# RN831X_RN861X_MCU register map
File version: v0.0.1
CPU: RN831X_RN861X_MCU r1p0, little endian, MPU, no FPU
Registers are 32-bit, read-write, reset 0x0 unless marked. A register's access mark holds for its fields unless they carry their own. Offsets are from the block's base; [hi:lo] are bit positions.

## QSPI0 — QSPI0 Module
Base 0xB0088000
Same registers: QSPI1 0xB008C000
0x00 SCKDIV access not given — Clock Divisor Register
  [11:0] SCKDIV — Clock divisor factor selection bits
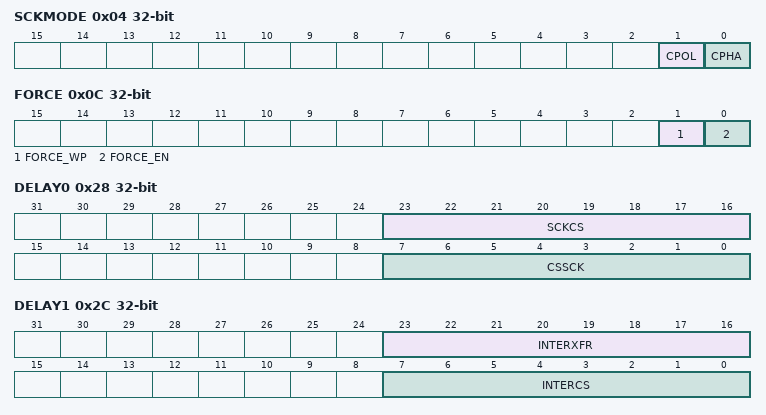
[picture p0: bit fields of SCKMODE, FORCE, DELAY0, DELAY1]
0x04 SCKMODE — Clock Mode Register (Master/Slave)
  [1] CPOL — Clock (SCK) Polarity selection bit.
  [0] CPHA — Clock (SCK) Phase selection bit. In DDR mode, only CPHA=0 is supported
0x08 SCKSAMPLE access not given — Sample Point Configuration Register (DDR Mode)
  [11:0] SCKSMP — DDR Mode SCK sample point delay selection bit
0x0C FORCE — Pin Output Force Register
  [1] FORCE_WP — WP (IO2) pin output state selection bit (when not used as data line). Invalid in Quad-line mode.
  [0] FORCE_EN — Force output enable for non-data pins in different interface modes.
0x10 CSID access not given — Chip Select ID Register
  [2:0] CSID — Chip Select device ID selection bit
0x14 CSDEF access not given — Chip Select Default Value Register
  [0] CSDEF — CS0 default (idle) state selection bit (Master mode)
0x18 CSMODE — Chip Select Mode Register
  [1:0] CSMODE — Chip Select mode selection bits. Use Hold mode for continuous data transfer, switch to Disable mode after transfer completes.
    0=AUTO (Auto mode); 2=HOLD (Hold mode); 3=DISABLE (Disable mode)
0x1C VERSION ro
  [31:0] VERSION — QSPI Version 2.1.0
0x20 ADDR_WRAP access not given — SPI Flash Start Address Offset Register
  [31:0] OFFSET — SPI Flash start address offset value
0x24 BOUNDARY_CFG access not given — SPI Flash Address Boundary Configuration Register
  [31:0] BOUNDARY — XIP boundary address configuration register
0x28 DELAY0 — Delay Control Register 0
  [23:16] SCKCS — Delay cycles from last valid SCK edge to CS deassertion (rising edge).
  [7:0] CSSCK — Delay cycles from CS assertion (falling edge) to first valid SCK rising edge.
0x2C DELAY1 — Delay Control Register 1
  [23:16] INTERXFR — Delay cycles between two data frames.
  [7:0] INTERCS — Minimum delay cycles from CS deassertion (rising edge) to next CS assertion (falling edge).
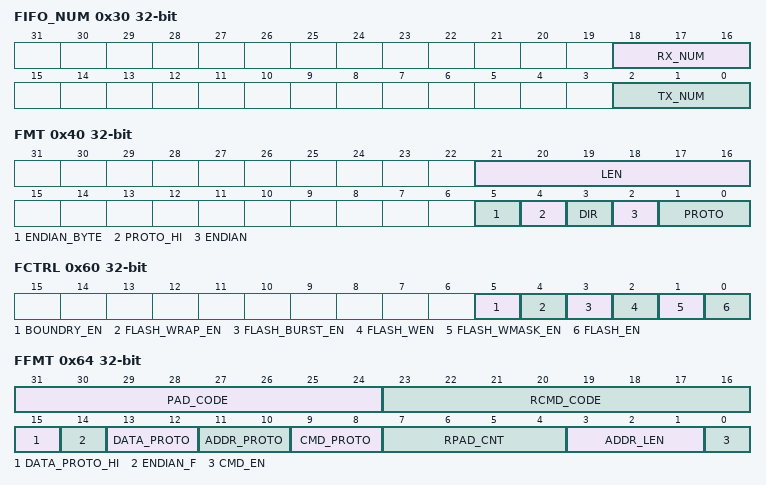
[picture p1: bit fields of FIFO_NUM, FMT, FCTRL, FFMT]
0x30 FIFO_NUM ro — FIFO Valid Data Count Register
  [18:16] RX_NUM — RX FIFO valid data count.
  [2:0] TX_NUM — TX FIFO valid data count.
0x34 TSIZE access not given — DMA Transfer Data Length Register.
  [31:0] TSIZE — transfer data length (in beats)
0x38 RSIZE access not given — DMA Receive Data Length Register.
  [31:0] RSIZE — receive data length (in beats).
0x40 FMT — Frame Format Register (Master/Slave, Non-XIP Mode)
  [21:16] LEN — Frame data bit width selection bits. Master mode supports 4-32 bits, Slave mode supports 8/16/32 bits.
    8=8BIT (Data length for SPI transfer: 8 bits); 16=16BIT (Data length for SPI transfer: 16 bits); 32=32BIT (Data length for SPI transfer: 32 bits)
  [5] ENDIAN_BYTE — Byte endianness (transmission order within 32-bit word).
  [4] PROTO_HI — High bit extension for QSPI_FMT.PROTO[1:0] (See PROTO below).
  [3] DIR — Pin data transfer direction selection bit (for configurable I/O pins).
  [2] ENDIAN — Bit endianness (transmission order within byte).
  [1:0] PROTO — Interface mode (number of data lines) selection bits.
    0=SINGLE (Single-line mode); 1=DUAL (Dual-line mode); 2=QUAD (Quad-line mode); 3=HALF_DUPLEX (Single-line Half-duplex mode)
0x48 TXDATA access not given — Transmit Data Register (Master/Slave)
  [31:0] TXDATA — Transmit data buffer. Valid data width depends on QSPI_FMT.LEN register configuration.
0x4C RXDATA ro — Receive Data Register (Master/Slave)
  [31:0] RXDATA — Receive data buffer. Valid data width depends on QSPI_FMT.LEN register configuration.
0x50 TX_MARK — Transmit FIFO Threshold Register (Master/Slave)
  [2:0] TX_MARK — ransmit FIFO threshold selection bit. Interrupt flag tx_irq is raised when TX FIFO valid data count is less than this threshold.
    1=1 valid data item; 2=2 valid data items; 3=3 valid data items; 4=4 valid data items
0x54 RX_MARK — Receive FIFO Threshold Register (Master/Slave)
  [2:0] RX_MARK — Receive FIFO threshold selection bit. Interrupt flag rx_irq is raised when RX FIFO valid data count exceeds this threshold.
    0=0 valid data item; 1=1 valid data item; 2=2 valid data items; 3=3 valid data items
0x60 FCTRL — SPI Flash Interface Control Register (XIP)
  [5] BOUNDRY_EN — XIP Mode Boundary Address Enable bit
  [4] FLASH_WRAP_EN — Data value for fixed data measurement mode. The measurement register is updated only when this data is received
  [3] FLASH_BURST_EN — Measurement End Point
  [2] FLASH_WEN — Measurement Start Point
  [1] FLASH_WMASK_EN — Measurement Mode
  [0] FLASH_EN — XIP Mode Enable bit.
0x64 FFMT — SPI Flash Command Format Register (XIP)
  [31:24] PAD_CODE — First 8 bits of data transmitted during dummy cycles.
  [23:16] RCMD_CODE — SPI Flash Read Instruction Opcode.
  [15] DATA_PROTO_HI — High bit extension for QSPI_FFMT.DATA_PROTO[1:0] (See DATA_PROTO).
  [14] ENDIAN_F — XIP Mode bit endianness (transmission order within byte). This bit does not change byte order, only the bit order within a single byte.
  [13:12] DATA_PROTO — Data Phase Interface Mode selection bits.
    0=SINGLE (XIP Data Single-line mode); 1=DUAL (XIP Data Dual-line mode); 2=QUAD (XIP Data Quad-line mode); 3=HALF_DUPLEX (XIP Data Single-line Half-duplex mode)
  [11:10] ADDR_PROTO — Address Phase Interface Mode selection bits.
    0=SINGLE (XIP Address Single-line mode); 1=DUAL (XIP Address Dual-line mode); 2=QUAD (XIP Address Quad-line mode)
  [9:8] CMD_PROTO — Command Phase Interface Mode selection bits.
    0=SINGLE (XIP Command Single-line mode); 1=DUAL (XIP Command Dual-line mode); 2=QUAD (XIP Command Quad-line mode)
  [7:4] RPAD_CNT — Read instruction dummy cycle count selection bits (Lower 4 bits). The 5th bit (MSB) of RPAD_CNT is configured in FFMT1.RPAD_CNT_H.
  [3:1] ADDR_LEN — Address Length selection bits.
    0=NONE (Skip Address phase); 1=8BIT (Address Length 8 bits); 2=16BIT (Address Length 16 bits); 3=24BIT (Address Length 24 bits (default)); 4=32BIT (Address Length 32 bits)
  [0] CMD_EN — Instruction Send Enable bit.
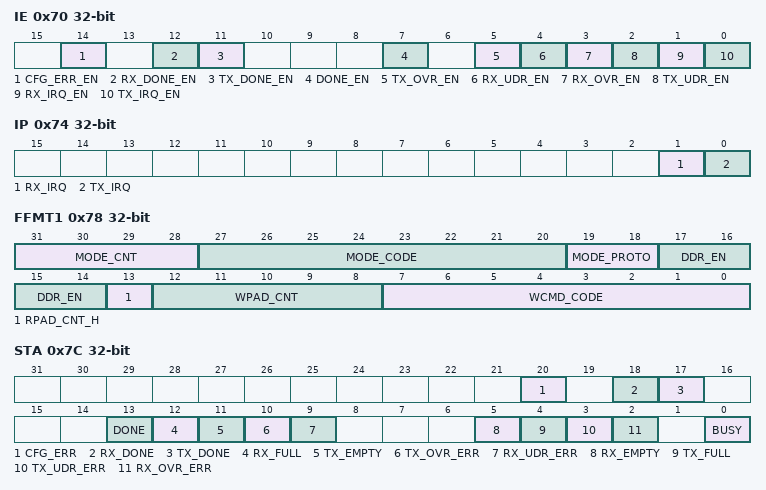
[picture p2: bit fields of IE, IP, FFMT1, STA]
0x70 IE — Interrupt Enable Register (Master/Slave)
  [14] CFG_ERR_EN — Configuration Frame Error Interrupt Enable bit.
  [12] RX_DONE_EN — (DMA) Receive Done Interrupt Enable bit.
  [11] TX_DONE_EN — (DMA) Transmit Done Interrupt Enable bit.
  [7] DONE_EN — Transfer Done Interrupt Enable bit.
  [5] TX_OVR_EN — Transmit FIFO Overflow Interrupt Enable bit.
  [4] RX_UDR_EN — Receive FIFO Underflow Interrupt Enable bit.
  [3] RX_OVR_EN — Receive FIFO Overflow Interrupt Enable bit.
  [2] TX_UDR_EN — Transmit FIFO Underflow Interrupt Enable bit.
  [1] RX_IRQ_EN — Receive FIFO Threshold Interrupt Enable bit.
  [0] TX_IRQ_EN — Transmit FIFO Threshold Interrupt Enable bit
0x74 IP ro — Interrupt Pending Register (Master/Slave)
  [1] RX_IRQ — Receive FIFO Threshold Interrupt Flag. Set when RX FIFO valid data count exceeds RX_MARK threshold.
  [0] TX_IRQ — Transmit FIFO Threshold Interrupt Flag. Set when TX FIFO valid data count is less than TX_MARK threshold.
0x78 FFMT1 — SPI Flash Command Format Register 1 (XIP)
  [31:28] MODE_CNT — Mode Byte Length selection bits.
  [27:20] MODE_CODE — SPI Flash Mode Byte.
  [19:18] MODE_PROTO — Mode Byte Phase Interface Mode selection bits.
    0=SINGLE (XIP Mode Single-line mode); 1=DUAL (XIP Mode Dual-line mode); 2=QUAD (XIP Mode Quad-line mode)
  [17:14] DDR_EN — DDR Enable bits for different phases: Instruction[14], Address[15], Mode[16], Data[17].
  [13] RPAD_CNT_H — High bit (Bit 4) for read instruction dummy cycle count selection. Lower 4 bits are in FFMT.RPAD_CNT.
  [12:8] WPAD_CNT — Write instruction dummy cycle count selection bits.
  [7:0] WCMD_CODE — SPI Flash Write Instruction Opcode.
0x7C STA access per field — Status Register
  [20] CFG_ERR rw write-1-clears — Frame Configuration Error Flag. Set when a frame config error occurs in normal QSPI or XIP mode.
  [18] RX_DONE rw write-1-clears — DMA Receive Done Flag. Set when received data count reaches RSIZE.
  [17] TX_DONE rw write-1-clears — DMA Transmit Done Flag. Set when transmitted data count reaches TSIZE.
  [13] DONE rw write-1-clears — Transfer Done Flag. Set when a data transfer is complete (send/receive finished) and TX FIFO is empty.
  [12] RX_FULL ro — Receive FIFO Full Flag.
  [11] TX_EMPTY ro — Transmit FIFO Empty Flag.
  [10] TX_OVR_ERR rw write-1-clears — Transmit FIFO Overflow Error Flag. Set if QSPI_TXDATA is written while TX FIFO is full.
  [9] RX_UDR_ERR rw write-1-clears — Receive FIFO Underflow Error Flag. Set if QSPI_RXDATA is read while RX FIFO is empty.
  [5] RX_EMPTY ro — Receive FIFO Empty Flag.
  [4] TX_FULL ro — Transmit FIFO Full Flag.
  [3] TX_UDR_ERR rw write-1-clears — Transmit FIFO Underflow Error Flag.
  [2] RX_OVR_ERR rw write-1-clears — Receive FIFO Overflow Error Flag.
  [0] BUSY ro — Transfer Busy Flag (Master/Slave)
0x80 SDR_SCKSAMPLE access not given — Sample Point Configuration Register (SDR Mode)
  [11:0] SDR_SCKSAMPLE — SDR Mode SCK sample point delay selection bit.
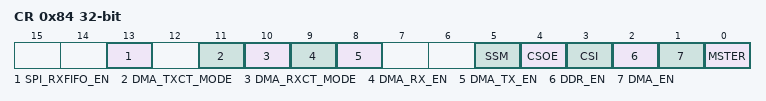
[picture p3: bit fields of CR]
0x84 CR — Control Register
  [13] SPI_RXFIFO_EN — Receive FIFO Enable bit.
  [11] DMA_TXCT_MODE — DMA Continuous Transmit Mode Enable bit.
  [10] DMA_RXCT_MODE — DMA Continuous Receive Mode Enable bit.
  [9] DMA_RX_EN — Receive DMA Mode Enable bit.
  [8] DMA_TX_EN — Transmit DMA Mode Enable bit.
  [5] SSM — Software Slave Management (CS) Enable bit.
  [4] CSOE — Master Mode Chip Select Output Enable bit.
  [3] CSI — Software-controlled Chip Select state (Slave mode, valid when SSM=1).
  [2] DDR_EN — DDR Mode Enable bit (Master mode only).
  [1] DMA_EN — DMA Mode Enable bit.
  [0] MSTER — Master/Slave Mode Selection bit.
